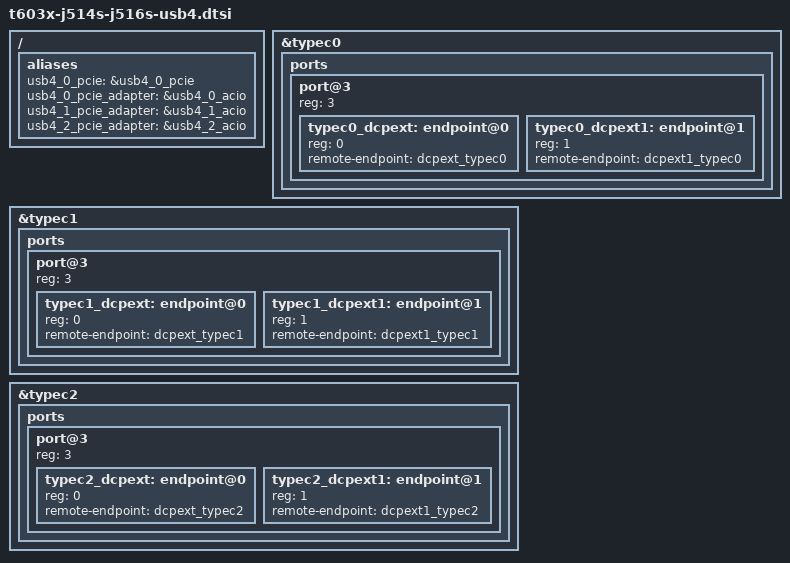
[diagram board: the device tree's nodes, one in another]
// SPDX-License-Identifier: GPL-2.0+ OR MIT
/* Additional loader aliases for the T6030 PCIe adapter tunables. */

/ {
	aliases {
		usb4_0_pcie = &usb4_0_pcie;
		usb4_0_pcie_adapter = &usb4_0_acio;
		usb4_1_pcie_adapter = &usb4_1_acio;
		usb4_2_pcie_adapter = &usb4_2_acio;
	};
};

&typec0 {
	ports {
		port@3 {
			reg = <3>;
			#address-cells = <1>;
			#size-cells = <0>;

			typec0_dcpext: endpoint@0 {
				reg = <0>;
				remote-endpoint = <&dcpext_typec0>;
			};

			typec0_dcpext1: endpoint@1 {
				reg = <1>;
				remote-endpoint = <&dcpext1_typec0>;
			};
		};
	};
};

&typec1 {
	ports {
		port@3 {
			reg = <3>;
			#address-cells = <1>;
			#size-cells = <0>;

			typec1_dcpext: endpoint@0 {
				reg = <0>;
				remote-endpoint = <&dcpext_typec1>;
			};

			typec1_dcpext1: endpoint@1 {
				reg = <1>;
				remote-endpoint = <&dcpext1_typec1>;
			};
		};
	};
};

&typec2 {
	ports {
		port@3 {
			reg = <3>;
			#address-cells = <1>;
			#size-cells = <0>;

			typec2_dcpext: endpoint@0 {
				reg = <0>;
				remote-endpoint = <&dcpext_typec2>;
			};

			typec2_dcpext1: endpoint@1 {
				reg = <1>;
				remote-endpoint = <&dcpext1_typec2>;
			};
		};
	};
};
